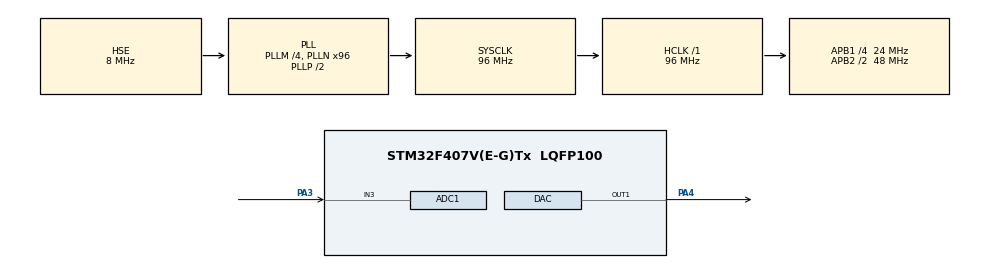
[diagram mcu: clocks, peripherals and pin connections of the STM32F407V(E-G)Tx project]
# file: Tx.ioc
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ADC1.Channel-9\#ChannelRegularConversion=ADC_CHANNEL_3
ADC1.ContinuousConvMode=ENABLE
ADC1.DMAContinuousRequests=ENABLE
ADC1.EOCSelection=ADC_EOC_SEQ_CONV
ADC1.ExternalTrigConv=ADC_EXTERNALTRIGCONV_T8_TRGO
ADC1.InjNumberOfConversion=0
ADC1.NbrOfConversionFlag=1
ADC1.Rank-9\#ChannelRegularConversion=1
ADC1.SamplingTime-9\#ChannelRegularConversion=ADC_SAMPLETIME_15CYCLES
ADC1.master=1
DAC.DAC_OutputBuffer=DAC_OUTPUTBUFFER_ENABLE
DAC.DAC_Trigger=DAC_TRIGGER_T8_TRGO
Dma.ADC1.1.Direction=DMA_PERIPH_TO_MEMORY
Dma.ADC1.1.FIFOMode=DMA_FIFOMODE_DISABLE
Dma.ADC1.1.Instance=DMA2_Stream0
Dma.ADC1.1.MemDataAlignment=DMA_MDATAALIGN_HALFWORD
Dma.ADC1.1.MemInc=DMA_MINC_ENABLE
Dma.ADC1.1.Mode=DMA_CIRCULAR
Dma.ADC1.1.PeriphDataAlignment=DMA_PDATAALIGN_HALFWORD
Dma.ADC1.1.PeriphInc=DMA_PINC_DISABLE
Dma.ADC1.1.Priority=DMA_PRIORITY_VERY_HIGH
Dma.DAC1.0.Direction=DMA_MEMORY_TO_PERIPH
Dma.DAC1.0.FIFOMode=DMA_FIFOMODE_DISABLE
Dma.DAC1.0.Instance=DMA1_Stream5
Dma.DAC1.0.MemDataAlignment=DMA_MDATAALIGN_HALFWORD
Dma.DAC1.0.MemInc=DMA_MINC_ENABLE
Dma.DAC1.0.Mode=DMA_CIRCULAR
Dma.DAC1.0.PeriphDataAlignment=DMA_PDATAALIGN_HALFWORD
Dma.DAC1.0.PeriphInc=DMA_PINC_DISABLE
Dma.DAC1.0.Priority=DMA_PRIORITY_VERY_HIGH
Dma.Request0=DAC1
Dma.Request1=ADC1
Mcu.Family=STM32F4
Mcu.Name=STM32F407V(E-G)Tx
Mcu.Package=LQFP100
NVIC.ADC_IRQn=true\:0\:0\:false\:false\:true\:true\:true\:true
NVIC.DMA1_Stream5_IRQn=true\:0\:0\:false\:false\:true\:false\:true\:true
NVIC.DMA2_Stream0_IRQn=true\:0\:0\:false\:false\:true\:false\:true\:true
NVIC.PriorityGroup=NVIC_PRIORITYGROUP_4
PA13.Mode=Serial_Wire
PA13.Signal=SYS_JTMS-SWDIO
PA14.Mode=Serial_Wire
PA14.Signal=SYS_JTCK-SWCLK
PA3.Signal=ADCx_IN3
PA4.GPIO_Mode=GPIO_MODE_ANALOG
PA4.Signal=COMP_DAC1_group
PH0-OSC_IN.Mode=HSE-External-Oscillator
PH0-OSC_IN.Signal=RCC_OSC_IN
PH1-OSC_OUT.Mode=HSE-External-Oscillator
PH1-OSC_OUT.Signal=RCC_OSC_OUT
ProjectManager.HeapSize=0x200
ProjectManager.StackSize=0x400
ProjectManager.TargetToolchain=STM32CubeIDE
RCC.48MHZClocksFreq_Value=48000000
RCC.AHBFreq_Value=96000000
RCC.APB1CLKDivider=RCC_HCLK_DIV4
RCC.APB1Freq_Value=24000000
RCC.APB1TimFreq_Value=48000000
RCC.APB2CLKDivider=RCC_HCLK_DIV2
RCC.APB2Freq_Value=48000000
RCC.APB2TimFreq_Value=96000000
RCC.CortexFreq_Value=96000000
RCC.HCLKFreq_Value=96000000
RCC.HSE_VALUE=8000000
RCC.HSI_VALUE=16000000
RCC.LSE_VALUE=32768
RCC.PLLM=4
RCC.PLLN=96
RCC.PLLSourceVirtual=RCC_PLLSOURCE_HSE
RCC.SYSCLKFreq_VALUE=96000000
RCC.SYSCLKSource=RCC_SYSCLKSOURCE_PLLCLK
RCC.VCOOutputFreq_Value=192000000
SH.ADCx_IN3.0=ADC1_IN3,IN3
SH.COMP_DAC1_group.0=DAC_OUT1,DAC_OUT1
TIM8.Period=10-1
TIM8.Prescaler=100-1
TIM8.TIM_MasterOutputTrigger=TIM_TRGO_UPDATE
VP_TIM8_VS_ClockSourceINT.Mode=Internal
board=custom

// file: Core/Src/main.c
/* USER CODE BEGIN Header */
/**
  ******************************************************************************
  * @file           : main.c
  * @brief          : Main program body
  ******************************************************************************
  * @attention
  *
  * Copyright (c) 2025 STMicroelectronics.
  * All rights reserved.
  *
  * This software is licensed under terms that can be found in the LICENSE file
  * in the root directory of this software component.
  * If no LICENSE file comes with this software, it is provided AS-IS.
  *
  ******************************************************************************
  */
/* USER CODE END Header */
#include "main.h"

/* USER CODE BEGIN Includes */
#include "arm_math.h"
#include "arm_math_types_f16.h"
#include "iir.h"
#include "stdio.h"
/* USER CODE END Includes */

/* USER CODE BEGIN PD */
#define ADC_SAMPLE_RATE 96000
#define ADC_BUFFER_SIZE 64
#define SINE_TABLE_SIZE 8
#define DAC_BUFFER_SIZE ADC_BUFFER_SIZE
#define BLOCK_SIZE (ADC_BUFFER_SIZE/2)
#define NUM_STAGE_IIR 3
#define NUM_STD_COEFFS 5
/* USER CODE END PD */

ADC_HandleTypeDef hadc1;
DMA_HandleTypeDef hdma_adc1;

DAC_HandleTypeDef hdac;
DMA_HandleTypeDef hdma_dac1;

TIM_HandleTypeDef htim8;

/* USER CODE BEGIN PV */

// DMA buffers for ADC and DAC
float32_t print_data=0;
uint16_t adcBuffer[ADC_BUFFER_SIZE];
uint32_t dacBuffer[DAC_BUFFER_SIZE];
// Signal processing buffers
float32_t sineTable[SINE_TABLE_SIZE];     // Carrier wave lookup table
float32_t adcValue[ADC_BUFFER_SIZE];      // ADC samples converted to float
float32_t modulatedSignal[DAC_BUFFER_SIZE]; // Buffer for modulated signal
float32_t *modulatedSignalPtr = &modulatedSignal[0];

// IIR filter buffers and structure
float32_t filt_out_BPF[ADC_BUFFER_SIZE];  // Output buffer for filtered signal
float32_t *filt_out_BPF_ptr = &filt_out_BPF[0];

// IIR filter structure and state variables
filter_iir_t iir_filter;
float32_t iir_State_BPF[2*NUM_STAGE_IIR];
float32_t coefficients[NUM_STAGE_IIR * NUM_STD_COEFFS];
float32_t b[7] = { 0.00284896704954483,0,-0.00854690114863449,0,0.00854690114863449,0,-0.00284896704954483 };
float32_t a[6] = { -4.21179037467128,8.32172826164948,-9.56398610478042,6.74992484911049,-2.77045239474902,0.534195793129486 };
/* USER CODE END PV */

void SystemClock_Config(void);
static void MX_GPIO_Init(void);
static void MX_DMA_Init(void);
static void MX_DAC_Init(void);
static void MX_ADC1_Init(void);
static void MX_TIM8_Init(void);

/* USER CODE BEGIN 0 */

void HAL_ADC_ConvHalfCpltCallback(ADC_HandleTypeDef *hadc){
	static uint32_t sineIndex=0;
	filt_out_BPF[ADC_BUFFER_SIZE/2] = 0;
	for(uint32_t i=0;i<ADC_BUFFER_SIZE/2;i++){
		adcValue[i]=(float32_t)((adcBuffer[i]/4095.0f)*3.3f);
	}
	for(uint32_t i=0;i<ADC_BUFFER_SIZE/2;i++){
		modulatedSignal[i]=adcValue[i]*sineTable[sineIndex];
		sineIndex=(sineIndex+1)%SINE_TABLE_SIZE;
	}
	for(uint32_t i=0;i<ADC_BUFFER_SIZE/2;i++){
		filt_out_BPF[i]=filter_iir_apply(&iir_filter, modulatedSignal[i]);
	}
	//arm_biquad_cascade_df2T_f32(&iir_filter_BPF, modulatedSignalPtr, filt_out_BPF_ptr, BLOCK_SIZE);
	for(int i=0;i<DAC_BUFFER_SIZE/2;i++){
	    dacBuffer[i] = (uint32_t)((filt_out_BPF[i]/3.3f)*4095);
	}
}

void HAL_ADC_ConvCpltCallback(ADC_HandleTypeDef *hadc){
	static uint32_t sineIndex=0;
	for(uint32_t i=ADC_BUFFER_SIZE/2;i<ADC_BUFFER_SIZE;i++){
		adcValue[i]=(float32_t)((adcBuffer[i]/4095.0f)*3.3f);
	}
	for(uint32_t i=ADC_BUFFER_SIZE/2;i<ADC_BUFFER_SIZE;i++){
		modulatedSignal[i]=adcValue[i]*sineTable[sineIndex];
		sineIndex=(sineIndex+1)%SINE_TABLE_SIZE;
	}
	for(uint32_t i=ADC_BUFFER_SIZE/2;i<ADC_BUFFER_SIZE;i++){
		filt_out_BPF[i]=filter_iir_apply(&iir_filter, modulatedSignal[i]);
	}
	//arm_biquad_cascade_df2T_f32(&iir_filter_BPF, modulatedSignalPtr+BLOCK_SIZE, filt_out_BPF_ptr+BLOCK_SIZE, BLOCK_SIZE);
	for(int i=DAC_BUFFER_SIZE/2;i<DAC_BUFFER_SIZE;i++){
		dacBuffer[i]=(uint32_t)((filt_out_BPF[i]/3.3f)*4095);
	}
}

void GenerateSineWave(void){
	for(int i=0; i<SINE_TABLE_SIZE;i++){
		sineTable[i]=arm_sin_f32(2.0f*PI*i/SINE_TABLE_SIZE)*1.65+1.65;
	}
}

void InitializeIIRFilter(void) {
    // Initialize the IIR filter structure
    //arm_biquad_cascade_df2T_init_f32(&iir_filter_BPF, NUM_STAGE_IIR, coeffs, iir_State_BPF);
    float32_t buffer[64] = {0};
    filter_iir_init(&iir_filter, b, a, 6, buffer);
}
/* USER CODE END 0 */

int main(void)
{

  /* MCU Configuration--------------------------------------------------------*/

  /* Reset of all peripherals, Initializes the Flash interface and the Systick. */
  HAL_Init();

  /* Configure the system clock */
  SystemClock_Config();

  /* Initialize all configured peripherals */
  MX_GPIO_Init();
  MX_DMA_Init();
  MX_DAC_Init();
  MX_ADC1_Init();
  MX_TIM8_Init();
  /* USER CODE BEGIN 2 */
  GenerateSineWave();
  InitializeIIRFilter();

  HAL_TIM_Base_Start(&htim8);
  HAL_ADC_Start_DMA(&hadc1, (uint32_t*)&adcBuffer, ADC_BUFFER_SIZE);
  if(HAL_DAC_Start_DMA(&hdac, DAC_CHANNEL_1, (const uint32_t*)&dacBuffer, DAC_BUFFER_SIZE, DAC_ALIGN_12B_R)!=HAL_OK){
	  Error_Handler();

  };
  HAL_TIM_Base_Start(&htim8);
  /* USER CODE END 2 */

  /* Infinite loop */
  while (1)
  {

  }
}

void SystemClock_Config(void)
{
  RCC_OscInitTypeDef RCC_OscInitStruct = {0};
  RCC_ClkInitTypeDef RCC_ClkInitStruct = {0};

  /** Configure the main internal regulator output voltage
  */
  __HAL_RCC_PWR_CLK_ENABLE();
  __HAL_PWR_VOLTAGESCALING_CONFIG(PWR_REGULATOR_VOLTAGE_SCALE1);

  /** Initializes the RCC Oscillators according to the specified parameters
  * in the RCC_OscInitTypeDef structure.
  */
  RCC_OscInitStruct.OscillatorType = RCC_OSCILLATORTYPE_HSE;
  RCC_OscInitStruct.HSEState = RCC_HSE_ON;
  RCC_OscInitStruct.PLL.PLLState = RCC_PLL_ON;
  RCC_OscInitStruct.PLL.PLLSource = RCC_PLLSOURCE_HSE;
  RCC_OscInitStruct.PLL.PLLM = 4;
  RCC_OscInitStruct.PLL.PLLN = 96;
  RCC_OscInitStruct.PLL.PLLP = RCC_PLLP_DIV2;
  RCC_OscInitStruct.PLL.PLLQ = 4;
  if (HAL_RCC_OscConfig(&RCC_OscInitStruct) != HAL_OK)
  {
    Error_Handler();
  }

  /** Initializes the CPU, AHB and APB buses clocks
  */
  RCC_ClkInitStruct.ClockType = RCC_CLOCKTYPE_HCLK|RCC_CLOCKTYPE_SYSCLK
                              |RCC_CLOCKTYPE_PCLK1|RCC_CLOCKTYPE_PCLK2;
  RCC_ClkInitStruct.SYSCLKSource = RCC_SYSCLKSOURCE_PLLCLK;
  RCC_ClkInitStruct.AHBCLKDivider = RCC_SYSCLK_DIV1;
  RCC_ClkInitStruct.APB1CLKDivider = RCC_HCLK_DIV4;
  RCC_ClkInitStruct.APB2CLKDivider = RCC_HCLK_DIV2;

  if (HAL_RCC_ClockConfig(&RCC_ClkInitStruct, FLASH_LATENCY_3) != HAL_OK)
  {
    Error_Handler();
  }
}

static void MX_ADC1_Init(void)
{

  ADC_ChannelConfTypeDef sConfig = {0};

  /** Configure the global features of the ADC (Clock, Resolution, Data Alignment and number of conversion)
  */
  hadc1.Instance = ADC1;
  hadc1.Init.ClockPrescaler = ADC_CLOCK_SYNC_PCLK_DIV2;
  hadc1.Init.Resolution = ADC_RESOLUTION_12B;
  hadc1.Init.ScanConvMode = DISABLE;
  hadc1.Init.ContinuousConvMode = ENABLE;
  hadc1.Init.DiscontinuousConvMode = DISABLE;
  hadc1.Init.ExternalTrigConvEdge = ADC_EXTERNALTRIGCONVEDGE_RISING;
  hadc1.Init.ExternalTrigConv = ADC_EXTERNALTRIGCONV_T8_TRGO;
  hadc1.Init.DataAlign = ADC_DATAALIGN_RIGHT;
  hadc1.Init.NbrOfConversion = 1;
  hadc1.Init.DMAContinuousRequests = ENABLE;
  hadc1.Init.EOCSelection = ADC_EOC_SEQ_CONV;
  if (HAL_ADC_Init(&hadc1) != HAL_OK)
  {
    Error_Handler();
  }

  /** Configure for the selected ADC regular channel its corresponding rank in the sequencer and its sample time.
  */
  sConfig.Channel = ADC_CHANNEL_3;
  sConfig.Rank = 1;
  sConfig.SamplingTime = ADC_SAMPLETIME_15CYCLES;
  if (HAL_ADC_ConfigChannel(&hadc1, &sConfig) != HAL_OK)
  {
    Error_Handler();
  }

}

static void MX_DAC_Init(void)
{

  DAC_ChannelConfTypeDef sConfig = {0};

  /** DAC Initialization
  */
  hdac.Instance = DAC;
  if (HAL_DAC_Init(&hdac) != HAL_OK)
  {
    Error_Handler();
  }

  /** DAC channel OUT1 config
  */
  sConfig.DAC_Trigger = DAC_TRIGGER_T8_TRGO;
  sConfig.DAC_OutputBuffer = DAC_OUTPUTBUFFER_ENABLE;
  if (HAL_DAC_ConfigChannel(&hdac, &sConfig, DAC_CHANNEL_1) != HAL_OK)
  {
    Error_Handler();
  }

}

static void MX_TIM8_Init(void)
{

  TIM_ClockConfigTypeDef sClockSourceConfig = {0};
  TIM_MasterConfigTypeDef sMasterConfig = {0};

  htim8.Instance = TIM8;
  htim8.Init.Prescaler = 100-1;
  htim8.Init.CounterMode = TIM_COUNTERMODE_UP;
  htim8.Init.Period = 10-1;
  htim8.Init.ClockDivision = TIM_CLOCKDIVISION_DIV1;
  htim8.Init.RepetitionCounter = 0;
  htim8.Init.AutoReloadPreload = TIM_AUTORELOAD_PRELOAD_DISABLE;
  if (HAL_TIM_Base_Init(&htim8) != HAL_OK)
  {
    Error_Handler();
  }
  sClockSourceConfig.ClockSource = TIM_CLOCKSOURCE_INTERNAL;
  if (HAL_TIM_ConfigClockSource(&htim8, &sClockSourceConfig) != HAL_OK)
  {
    Error_Handler();
  }
  sMasterConfig.MasterOutputTrigger = TIM_TRGO_UPDATE;
  sMasterConfig.MasterSlaveMode = TIM_MASTERSLAVEMODE_DISABLE;
  if (HAL_TIMEx_MasterConfigSynchronization(&htim8, &sMasterConfig) != HAL_OK)
  {
    Error_Handler();
  }

}

static void MX_DMA_Init(void)
{

  /* DMA controller clock enable */
  __HAL_RCC_DMA1_CLK_ENABLE();
  __HAL_RCC_DMA2_CLK_ENABLE();

  /* DMA interrupt init */
  /* DMA1_Stream5_IRQn interrupt configuration */
  HAL_NVIC_SetPriority(DMA1_Stream5_IRQn, 0, 0);
  HAL_NVIC_EnableIRQ(DMA1_Stream5_IRQn);
  /* DMA2_Stream0_IRQn interrupt configuration */
  HAL_NVIC_SetPriority(DMA2_Stream0_IRQn, 0, 0);
  HAL_NVIC_EnableIRQ(DMA2_Stream0_IRQn);

}

static void MX_GPIO_Init(void)
{

  /* GPIO Ports Clock Enable */
  __HAL_RCC_GPIOH_CLK_ENABLE();
  __HAL_RCC_GPIOA_CLK_ENABLE();

}

void Error_Handler(void)
{
  __disable_irq();
  while (1)
  {
  }
}
